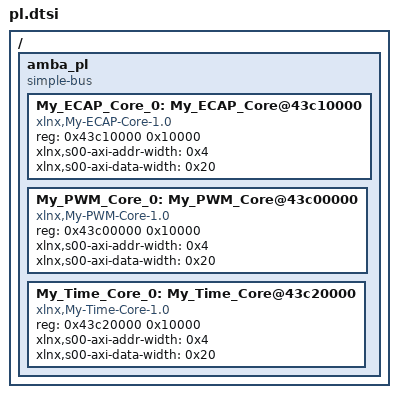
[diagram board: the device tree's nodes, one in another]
/*
 * CAUTION: This file is automatically generated by Xilinx.
 * Version: HSI 2015.4
 * Today is: Thu Sep  6 10:00:07 2018
*/


/ {
	amba_pl: amba_pl {
		#address-cells = <1>;
		#size-cells = <1>;
		compatible = "simple-bus";
		ranges ;
		My_ECAP_Core_0: My_ECAP_Core@43c10000 {
			compatible = "xlnx,My-ECAP-Core-1.0";
			reg = <0x43c10000 0x10000>;
			xlnx,s00-axi-addr-width = <0x4>;
			xlnx,s00-axi-data-width = <0x20>;
		};
		My_PWM_Core_0: My_PWM_Core@43c00000 {
			compatible = "xlnx,My-PWM-Core-1.0";
			reg = <0x43c00000 0x10000>;
			xlnx,s00-axi-addr-width = <0x4>;
			xlnx,s00-axi-data-width = <0x20>;
		};
		My_Time_Core_0: My_Time_Core@43c20000 {
			compatible = "xlnx,My-Time-Core-1.0";
			reg = <0x43c20000 0x10000>;
			xlnx,s00-axi-addr-width = <0x4>;
			xlnx,s00-axi-data-width = <0x20>;
		};
	};
};
